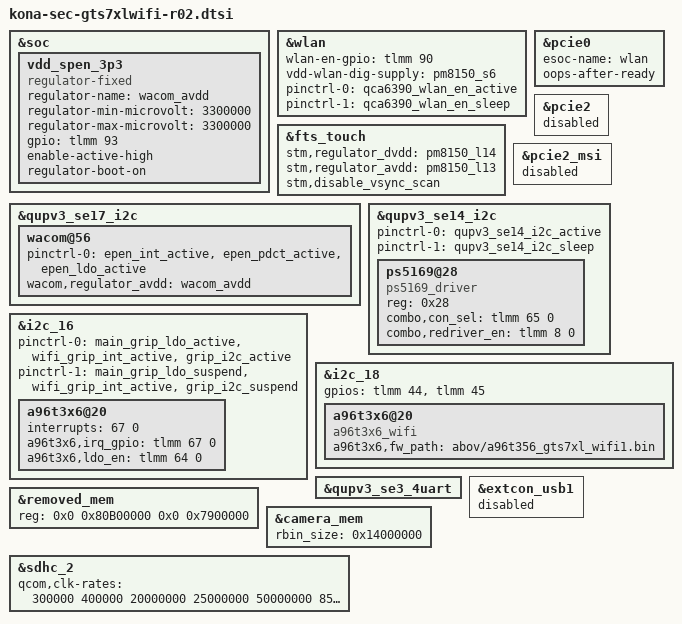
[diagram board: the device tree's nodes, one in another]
/* Copyright (c) 2020, The Linux Foundation. All rights reserved.
 *
 * This program is free software; you can redistribute it and/or modify
 * it under the terms of the GNU General Public License version 2 and
 * only version 2 as published by the Free Software Foundation.
 *
 * This program is distributed in the hope that it will be useful,
 * but WITHOUT ANY WARRANTY; without even the implied warranty of
 * MERCHANTABILITY or FITNESS FOR A PARTICULAR PURPOSE.  See the
 * GNU General Public License for more details.
 */


#include "kona-sec-gts7xlwifi-pinctrl-r02.dtsi"
#include "../gts7l/kona-sec-gts7-pm-common.dtsi"
#include "kona-sec-gts7xlwifi-pm-r02.dtsi"
#include "../drivers/gps_bcm47531.dtsi"
#include "../drivers/audio_gts7xl_common.dtsi"
#include "../drivers/displayport_gts7xl_r01.dtsi"
#include "../drivers/camera_sensor_gts7xl_r01.dtsi"
#include "../drivers/bluetooth_gts7xl_common.dtsi"
#include "../drivers/eif_gts7xl_common.dtsi"
#include "../drivers/input_gts7xl_common.dtsi"
#include "../drivers/battery-data-gts7xl-common.dtsi"
#include "../drivers/kona-sec-gts7xl-grip-r00.dtsi"
#include "../drivers/kona-sec-gts7xl-display-r01.dtsi"
#include "../drivers/fingerprint-sensor_gts7xl_r00.dtsi"

&soc {
	vdd_spen_3p3: vdd_spen_3p3 {
		compatible = "regulator-fixed";
		regulator-name = "wacom_avdd";
		regulator-min-microvolt = <3300000>;
		regulator-max-microvolt = <3300000>;
		gpio = <&tlmm 93 0>;
		enable-active-high;
		regulator-boot-on;
	};
};

&wlan {
	wlan-en-gpio = <&tlmm 90 0>;
	vdd-wlan-dig-supply = <&pm8150_s6>;
	pinctrl-0 = <&qca6390_wlan_en_active>;
	pinctrl-1 = <&qca6390_wlan_en_sleep>;
	status = "ok";
};

&fts_touch {
	stm,regulator_dvdd = "pm8150_l14";
	stm,regulator_avdd = "pm8150_l13";
	stm,disable_vsync_scan;
};

&qupv3_se17_i2c {
	wacom@56 {
		pinctrl-0 = <&epen_int_active &epen_pdct_active &epen_ldo_active>;
		wacom,regulator_avdd = "wacom_avdd";
	};
};

&pcie0 {
	esoc-name = "wlan";
	oops-after-ready;
};

&pcie2 {
    status = "disabled";
};

&pcie2_msi {
    status = "disabled";
};

&qupv3_se14_i2c {
	status = "ok";

	pinctrl-names = "default", "sleep";
	pinctrl-0 = <&qupv3_se14_i2c_active>;
	pinctrl-1 = <&qupv3_se14_i2c_sleep>;

	ps5169@28 {
		compatible = "ps5169_driver";
		reg = <0x28>;
		combo,con_sel = <&tlmm 65 0>;
		combo,redriver_en = <&tlmm 8 0>;
	};
};
/* remove WIFI GRIP since hw_rev02 device */
/delete-node/ &i2c_17;

/* MAIN GRIP */
&i2c_16 { /* SW I2C */
	pinctrl-0 = <&main_grip_ldo_active &wifi_grip_int_active &grip_i2c_active>;
	pinctrl-1 = <&main_grip_ldo_suspend &wifi_grip_int_active &grip_i2c_suspend>;
	a96t3x6@20 {
		interrupts = <67 0>;
		a96t3x6,irq_gpio = <&tlmm 67 0>;
		a96t3x6,ldo_en = <&tlmm 64 0>;
	};
};

/* change MAIN3/WIFI2 GRIP sensor to WIFI_GRIP since hw_rev02 device */
/* WIFI GRIP */
&i2c_18 { /* SW I2C */
    gpios = <&tlmm 44 0 /* sda */
         &tlmm 45 0 /* scl */
    >;
    a96t3x6@20 {
        compatible = "a96t3x6_wifi";
        a96t3x6,fw_path = "abov/a96t356_gts7xl_wifi1.bin";
    };
};

&qupv3_se3_4uart {
    status = "ok";
};

/*disable extcon_usb1 because of pm8150_gpio 10 conflict*/
&extcon_usb1 {
        status = "disabled";
};

/* TZapp region */
&removed_mem {
	reg = <0x0 0x80B00000 0x0 0x7900000>;
};

&camera_mem {
	rbin_size = <0x14000000>;
};

&sdhc_2 {
	qcom,clk-rates = <300000 400000 20000000 25000000
		50000000 85714285 201500000>;
};
